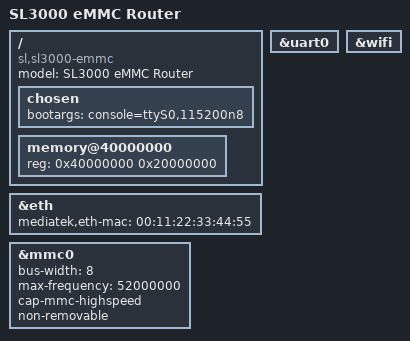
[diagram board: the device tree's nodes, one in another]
/dts-v1/;

#include "mt7981b.dtsi"

/ {
	model = "SL3000 eMMC Router";
	compatible = "sl,sl3000-emmc", "mediatek,mt7981b";

	chosen {
		bootargs = "console=ttyS0,115200n8";
	};

	memory@40000000 {
		device_type = "memory";
		reg = <0x40000000 0x20000000>;
	};
};

&uart0 {
	status = "okay";
};

&eth {
	status = "okay";
	mediatek,eth-mac = "00:11:22:33:44:55";
};

&wifi {
	status = "okay";
};

&mmc0 {
	status = "okay";
	bus-width = <8>;
	max-frequency = <52000000>;
	cap-mmc-highspeed;
	non-removable;
};
